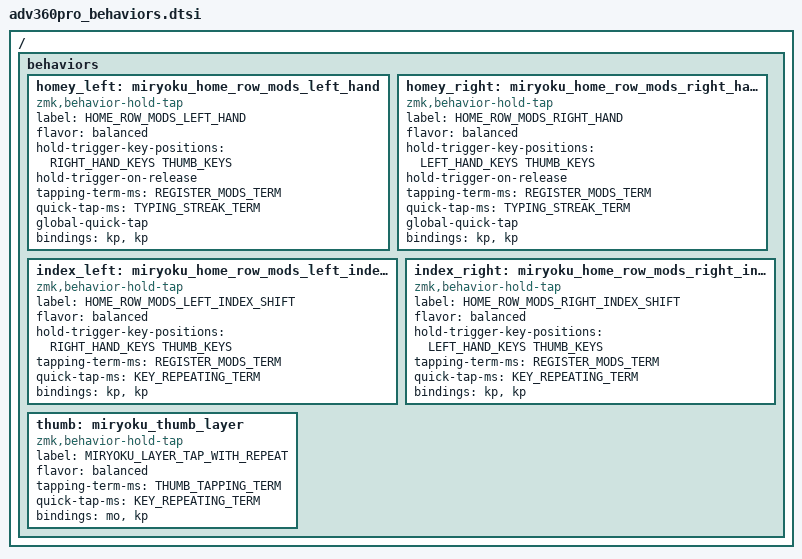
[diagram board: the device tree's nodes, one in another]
/* ADV360 Pro specific key positions */
#define LEFT_HAND_KEYS      \
          0  1  2  3  4  5     \
         12 13 14 15 16 17     \
         24 25 26 27 28 29     \
         36 37 38 39 40 41     \
            49 50 51 52

#define RIGHT_HAND_KEYS     \
             6  7  8  9 10 11  \
            18 19 20 21 22 23  \
            30 31 32 33 34 35  \
            42 43 44 45 46 47  \
               53 54 55 56

#define THUMB_KEYS          \
         48                57   \
            58 59     60 61

/ {
    behaviors {
        // ADV360-specific home row mods
        homey_left: miryoku_home_row_mods_left_hand {
            compatible = "zmk,behavior-hold-tap";
            label = "HOME_ROW_MODS_LEFT_HAND";
            flavor = "balanced";
            hold-trigger-key-positions = <RIGHT_HAND_KEYS THUMB_KEYS>;
            hold-trigger-on-release;
            tapping-term-ms = <REGISTER_MODS_TERM>;
            quick-tap-ms = <TYPING_STREAK_TERM>;
            global-quick-tap;
            #binding-cells = <2>;
            bindings = <&kp>, <&kp>;
        };

        homey_right: miryoku_home_row_mods_right_hand {
            compatible = "zmk,behavior-hold-tap";
            label = "HOME_ROW_MODS_RIGHT_HAND";
            flavor = "balanced";
            hold-trigger-key-positions = <LEFT_HAND_KEYS THUMB_KEYS>;
            hold-trigger-on-release;
            tapping-term-ms = <REGISTER_MODS_TERM>;
            quick-tap-ms = <TYPING_STREAK_TERM>;
            global-quick-tap;
            #binding-cells = <2>;
            bindings = <&kp>, <&kp>;
        };

        index_left: miryoku_home_row_mods_left_index_shift {
            compatible = "zmk,behavior-hold-tap";
            label = "HOME_ROW_MODS_LEFT_INDEX_SHIFT";
            flavor = "balanced";
            hold-trigger-key-positions = <RIGHT_HAND_KEYS THUMB_KEYS>;
            tapping-term-ms = <REGISTER_MODS_TERM>;
            quick-tap-ms = <KEY_REPEATING_TERM>;
            #binding-cells = <2>;
            bindings = <&kp>, <&kp>;
        };

        index_right: miryoku_home_row_mods_right_index_shift {
            compatible = "zmk,behavior-hold-tap";
            label = "HOME_ROW_MODS_RIGHT_INDEX_SHIFT";
            flavor = "balanced";
            hold-trigger-key-positions = <LEFT_HAND_KEYS THUMB_KEYS>;
            tapping-term-ms = <REGISTER_MODS_TERM>;
            quick-tap-ms = <KEY_REPEATING_TERM>;
            #binding-cells = <2>;
            bindings = <&kp>, <&kp>;
        };

        thumb: miryoku_thumb_layer {
            compatible = "zmk,behavior-hold-tap";
            label = "MIRYOKU_LAYER_TAP_WITH_REPEAT";
            flavor = "balanced";
            tapping-term-ms = <THUMB_TAPPING_TERM>;
            quick-tap-ms = <KEY_REPEATING_TERM>;
            #binding-cells = <2>;
            bindings = <&mo>, <&kp>;
        };
    };
}; 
